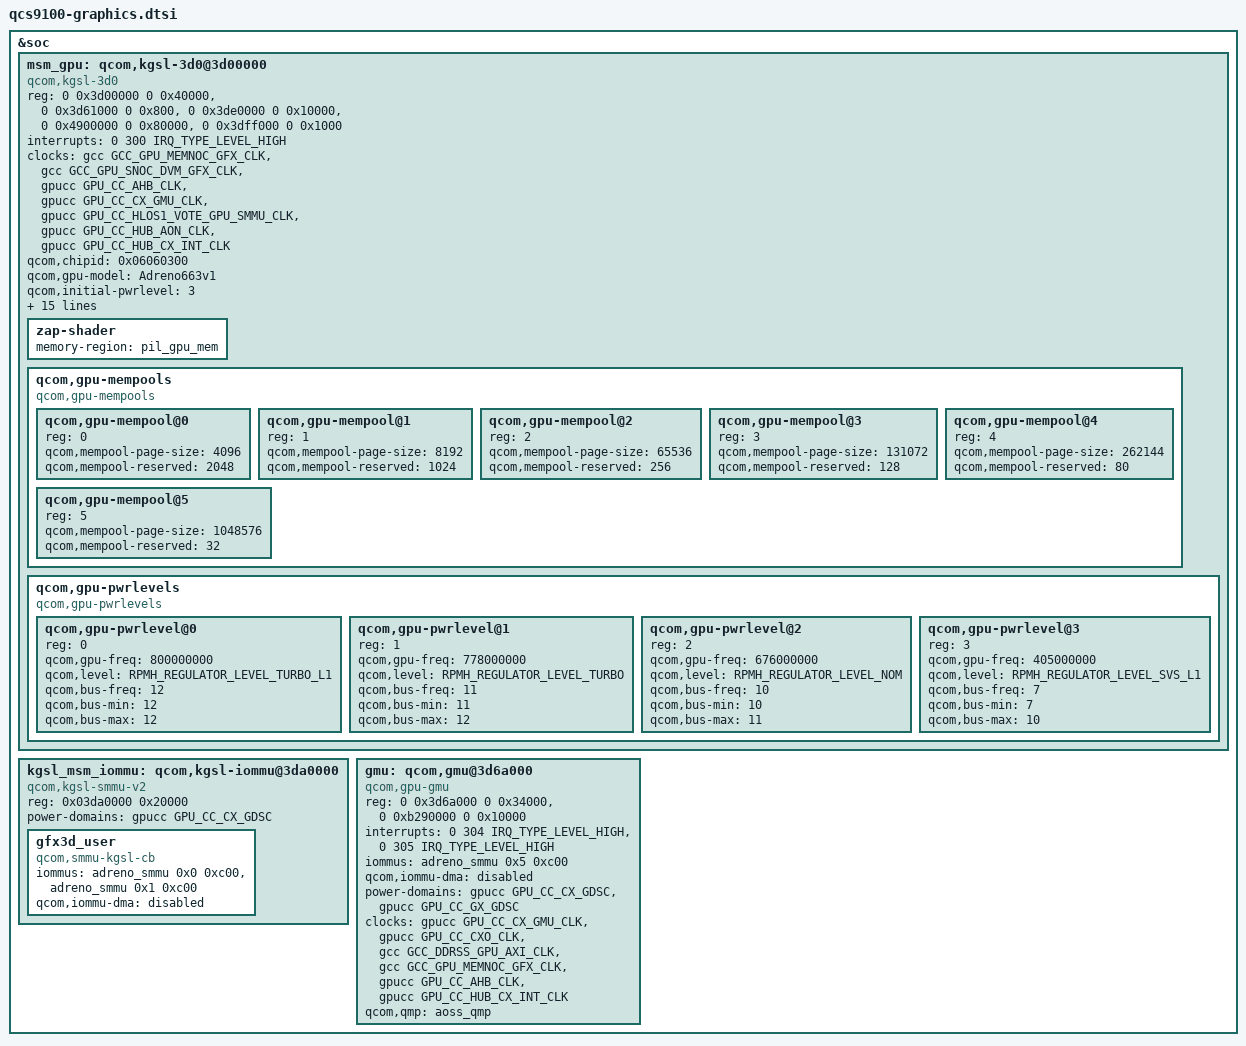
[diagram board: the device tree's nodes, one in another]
/*
 * Copyright (c) 2024 Qualcomm Innovation Center, Inc. All rights reserved.
 */
// SPDX-License-Identifier: BSD-3-Clause

#define MHZ_TO_KBPS(mhz, w) ((mhz * 1000000 * w) / (1024))

&soc {
	msm_gpu: qcom,kgsl-3d0@3d00000 {
		compatible = "qcom,kgsl-3d0";
		status = "ok";
		reg = <0 0x3d00000 0 0x40000>, <0 0x3d61000 0 0x800>,
			<0 0x3de0000 0 0x10000>, <0 0x4900000 0 0x80000>,
			<0 0x3dff000 0 0x1000>;
		reg-names = "kgsl_3d0_reg_memory", "cx_dbgc", "rscc",
			"qdss_gfx", "fusa";
		interrupts = <0 300 IRQ_TYPE_LEVEL_HIGH>;
		interrupt-names = "kgsl_3d0_irq";

		clocks = <&gcc GCC_GPU_MEMNOC_GFX_CLK>,
			<&gcc GCC_GPU_SNOC_DVM_GFX_CLK>,
			<&gpucc GPU_CC_AHB_CLK>,
			<&gpucc GPU_CC_CX_GMU_CLK>,
			<&gpucc GPU_CC_HLOS1_VOTE_GPU_SMMU_CLK>,
			<&gpucc GPU_CC_HUB_AON_CLK>,
			<&gpucc GPU_CC_HUB_CX_INT_CLK>;
		clock-names = "gcc_gpu_memnoc_gfx",
				"gcc_gpu_snoc_dvm_gfx",
				"gpu_cc_ahb",
				"gpu_cc_cx_gmu",
				"gpu_cc_hlos1_vote_gpu_smmu",
				"gpu_cc_hub_aon",
				"gpu_cc_hub_cx_int";

		qcom,chipid = <0x06060300>;
		qcom,gpu-model = "Adreno663v1";

		qcom,initial-pwrlevel = <3>;

		qcom,highest-bank-bit = <16>;

		qcom,min-access-length = <32>;

		qcom,ubwc-mode = <4>;

		qcom,gpu-qdss-stm = <0x161c0000 0x40000>; /* base addr, size */

		qcom,tzone-names = "gpuss-0-usr", "gpuss-1-usr";

		interconnect-names = "gpu_icc_path";
		interconnects = <&gem_noc MASTER_GFX3D 0 &mc_virt SLAVE_EBI1 0>;

		qcom,bus-table-ddr =
			<MHZ_TO_KBPS(0, 4)>,    /* index=0  */
			<MHZ_TO_KBPS(200, 4)>,  /* index=1  */
			<MHZ_TO_KBPS(451, 4)>,  /* index=2  */
			<MHZ_TO_KBPS(547, 4)>,  /* index=3  */
			<MHZ_TO_KBPS(681, 4)>,  /* index=4  */
			<MHZ_TO_KBPS(768, 4)>,  /* index=5  */
			<MHZ_TO_KBPS(1017, 4)>, /* index=6  */
			<MHZ_TO_KBPS(1353, 4)>, /* index=7  */
			<MHZ_TO_KBPS(1555, 4)>, /* index=8  */
			<MHZ_TO_KBPS(1708, 4)>, /* index=9  */
			<MHZ_TO_KBPS(2092, 4)>, /* index=10  */
			<MHZ_TO_KBPS(2736, 4)>, /* index=11  */
			<MHZ_TO_KBPS(3196, 4)>; /* index=12  */

		qcom,bus-table-cnoc =
			<0>,   /* Off */
			<100>; /* On */

		zap-shader {
			memory-region = <&pil_gpu_mem>;
		};

		qcom,gpu-mempools {
			#address-cells = <1>;
			#size-cells = <0>;
			compatible = "qcom,gpu-mempools";

			/* 4K Page Pool configuration */
			qcom,gpu-mempool@0 {
				reg = <0>;
				qcom,mempool-page-size = <4096>;
				qcom,mempool-reserved = <2048>;
			};
			/* 8K Page Pool configuration */
			qcom,gpu-mempool@1 {
				reg = <1>;
				qcom,mempool-page-size = <8192>;
				qcom,mempool-reserved = <1024>;
			};
			/* 64K Page Pool configuration */
			qcom,gpu-mempool@2 {
				reg = <2>;
				qcom,mempool-page-size = <65536>;
				qcom,mempool-reserved = <256>;
			};
			/* 128K Page Pool configuration */
			qcom,gpu-mempool@3 {
				reg = <3>;
				qcom,mempool-page-size = <131072>;
				qcom,mempool-reserved = <128>;
			};
			/* 256K Page Pool configuration */
			qcom,gpu-mempool@4 {
				reg = <4>;
				qcom,mempool-page-size = <262144>;
				qcom,mempool-reserved = <80>;
			};
			/* 1M Page Pool configuration */
			qcom,gpu-mempool@5 {
				reg = <5>;
				qcom,mempool-page-size = <1048576>;
				qcom,mempool-reserved = <32>;
			};
		};

		/* Power levels */
		qcom,gpu-pwrlevels {
			#address-cells = <1>;
			#size-cells = <0>;

			compatible = "qcom,gpu-pwrlevels";

			qcom,gpu-pwrlevel@0 {
				reg = <0>;
				qcom,gpu-freq = <800000000>;
				qcom,level = <RPMH_REGULATOR_LEVEL_TURBO_L1>;

				qcom,bus-freq = <12>;
				qcom,bus-min = <12>;
				qcom,bus-max = <12>;
			};

			qcom,gpu-pwrlevel@1 {
				reg = <1>;
				qcom,gpu-freq = <778000000>;
				qcom,level = <RPMH_REGULATOR_LEVEL_TURBO>;

				qcom,bus-freq = <11>;
				qcom,bus-min = <11>;
				qcom,bus-max = <12>;
			};

			qcom,gpu-pwrlevel@2 {
				reg = <2>;
				qcom,gpu-freq = <676000000>;
				qcom,level = <RPMH_REGULATOR_LEVEL_NOM>;

				qcom,bus-freq = <10>;
				qcom,bus-min = <10>;
				qcom,bus-max = <11>;
			};

			qcom,gpu-pwrlevel@3 {
				reg = <3>;
				qcom,gpu-freq = <405000000>;
				qcom,level = <RPMH_REGULATOR_LEVEL_SVS_L1>;

				qcom,bus-freq = <7>;
				qcom,bus-min = <7>;
				qcom,bus-max = <10>;
			};
		};
	};

	kgsl_msm_iommu: qcom,kgsl-iommu@3da0000 {
		#address-cells = <1>;
		#size-cells = <1>;

		compatible = "qcom,kgsl-smmu-v2";

		reg = <0x03da0000 0x20000>;

		power-domains = <&gpucc GPU_CC_CX_GDSC>;

		gfx3d_user: gfx3d_user {
			compatible = "qcom,smmu-kgsl-cb", "qcom,adreno";
			iommus = <&adreno_smmu 0x0 0xc00>, <&adreno_smmu 0x1 0xc00>;
			qcom,iommu-dma = "disabled";
		};
	};

	gmu: qcom,gmu@3d6a000 {
		compatible = "qcom,gpu-gmu";

		reg = <0 0x3d6a000 0 0x34000>,
			<0 0xb290000 0 0x10000>;

		reg-names = "kgsl_gmu_reg",
			"kgsl_gmu_pdc_cfg";

		interrupts = <0 304 IRQ_TYPE_LEVEL_HIGH>,
			<0 305 IRQ_TYPE_LEVEL_HIGH>;
		interrupt-names = "kgsl_hfi_irq", "kgsl_gmu_irq";

		iommus = <&adreno_smmu 0x5 0xc00>;
		qcom,iommu-dma = "disabled";

		power-domains = <&gpucc GPU_CC_CX_GDSC>, <&gpucc GPU_CC_GX_GDSC>;
		power-domain-names = "cx", "gx";

		clocks = <&gpucc GPU_CC_CX_GMU_CLK>,
			<&gpucc GPU_CC_CXO_CLK>,
			<&gcc GCC_DDRSS_GPU_AXI_CLK>,
			<&gcc GCC_GPU_MEMNOC_GFX_CLK>,
			<&gpucc GPU_CC_AHB_CLK>,
			<&gpucc GPU_CC_HUB_CX_INT_CLK>;

		clock-names = "gmu_clk", "cxo_clk", "axi_clk",
			"memnoc_clk", "ahb_clk", "hub_clk";

		qcom,qmp = <&aoss_qmp>;
	};
};
